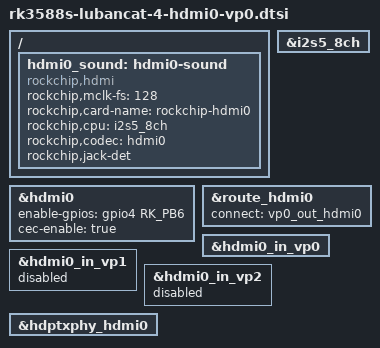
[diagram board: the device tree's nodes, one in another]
// SPDX-License-Identifier: (GPL-2.0+ OR MIT)
/*
 * Copyright (c) 2021 Rockchip Electronics Co., Ltd.
 * Copyright (c) 2023 EmbedFire <embedfire@embedfire.com>
 */

/ {
	hdmi0_sound: hdmi0-sound {
		status = "okay";
		compatible = "rockchip,hdmi";
		rockchip,mclk-fs = <128>;
		rockchip,card-name = "rockchip-hdmi0";
		rockchip,cpu = <&i2s5_8ch>;
		rockchip,codec = <&hdmi0>;
		rockchip,jack-det;
	};
};

&i2s5_8ch {
	status = "okay";
};

&hdmi0 {
	enable-gpios = <&gpio4 RK_PB6 GPIO_ACTIVE_HIGH>;
	cec-enable = "true";
	status = "okay";
};

&route_hdmi0{
	status = "okay";
	connect = <&vp0_out_hdmi0>;
};

&hdmi0_in_vp0 {
	status = "okay";
};

&hdmi0_in_vp1 {
	status = "disabled";
};

&hdmi0_in_vp2 {
	status = "disabled";
};

&hdptxphy_hdmi0 {
	status = "okay";
};
